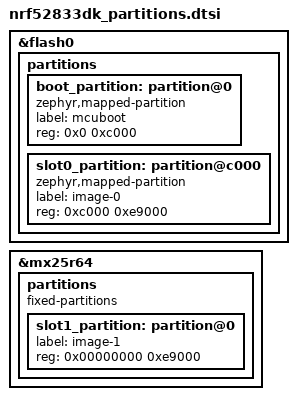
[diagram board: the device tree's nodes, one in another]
/*
 * Copyright (c) 2026 Nordic Semiconductor ASA
 *
 * SPDX-License-Identifier: LicenseRef-Nordic-5-Clause
 */

/delete-node/ &slot0_partition;

&flash0 {
	partitions {
		boot_partition: partition@0 {
			compatible = "zephyr,mapped-partition";
			label = "mcuboot";
			reg = <0x0 0xc000>;
		};

		slot0_partition: partition@c000 {
			compatible = "zephyr,mapped-partition";
			label = "image-0";
			reg = <0xc000 0xe9000>;
		};
	};
};

&mx25r64 {
	status = "okay";

	partitions {
		compatible = "fixed-partitions";
		#address-cells = <1>;
		#size-cells = <1>;

		slot1_partition: partition@0 {
			label = "image-1";
			reg = <0x00000000 0xe9000>;
		};
	};
};
